# SERDES_16G0 register map
Vendor: Texas Instruments
Registers are 32-bit, read-write, reset 0x0 unless marked. A register's access mark holds for its fields unless they carry their own. Offsets are as the file gives them; [hi:lo] are bit positions; {n}, {i} and the like mark numbered series.

## SERDES_16G0 (part 5 of 5)
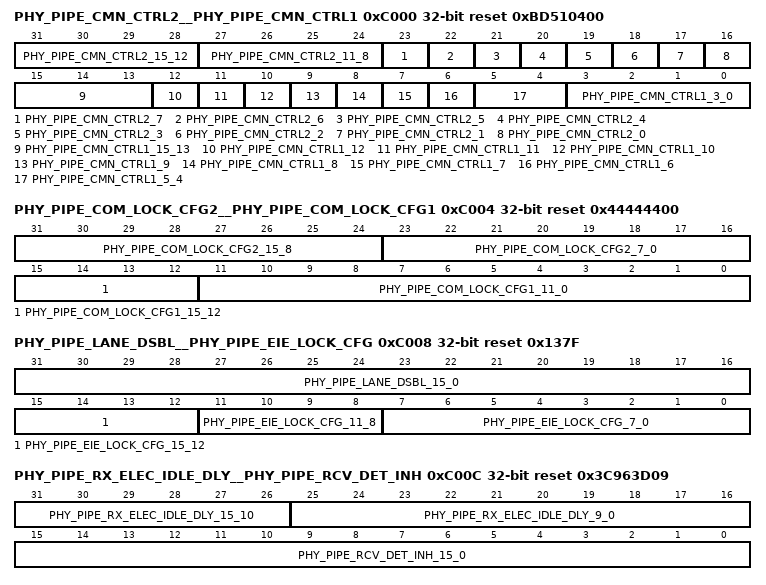
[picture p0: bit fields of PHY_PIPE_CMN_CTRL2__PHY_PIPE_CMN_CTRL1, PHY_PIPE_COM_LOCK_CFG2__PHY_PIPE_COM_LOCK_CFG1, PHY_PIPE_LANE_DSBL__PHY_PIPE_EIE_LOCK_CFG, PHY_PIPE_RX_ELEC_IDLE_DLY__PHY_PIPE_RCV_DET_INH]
0xC000 PHY_PIPE_CMN_CTRL2__PHY_PIPE_CMN_CTRL1 access not given reset 0xBD510400 — PIPE common control1 register
  [31:28] PHY_PIPE_CMN_CTRL2_15_12 rw — USB SuperSpeed Tx LFPS Stretch: Minimum number of data rate clock cycles in which PMA tx_lfps_en signal is asserted for USB SuperSpeed rate.
  [27:24] PHY_PIPE_CMN_CTRL2_11_8 rw — USB SuperSpeedPlus Tx LFPS Stretch: Minimum number of data rate clock cycles in which PMA tx_lfps_en signal is asserted for USB SuperSpeedPlus rate.
  [23] PHY_PIPE_CMN_CTRL2_7 rw — PCIe PIPE Gen 4 Rx mode:
  [22] PHY_PIPE_CMN_CTRL2_6 rw — TX electrical idle pre release: When this bit is set, the TX electrical idle release to the PMA is advanced 1 cycle to allow the adjustment of the data path timing
  [21] PHY_PIPE_CMN_CTRL2_5 rw — RX equalizer complete mask: When this bit is cleared, the PHY will return direction change of 0 when PMA indicates evaluation complete.
  [20] PHY_PIPE_CMN_CTRL2_4 rw — PCIe Gen 1/2 EIOS cycle error mask: When this bit is enabled and the pipe rx interface is outputting a PCIe Gen 1/2 EIOS symbol, decode errors will be masked out.
  [19] PHY_PIPE_CMN_CTRL2_3 rw — USB Gen 2 Bit Error Correction Disable: When this bit is high, bit error correction on SKP and SDS symbols is disabled.
  [18] PHY_PIPE_CMN_CTRL2_2 rw — USB PIPE3 Compatibility Mode enable: When this bit is set to 1, USB PIPE3 compatibility mode is enabled.
  [17] PHY_PIPE_CMN_CTRL2_1 rw — USB Loopback Slave Error Count disable: When this bit is set to 1, disables the error count for US loopback slave, such that the error count is not inserted into the BCNT OS.
  [16] PHY_PIPE_CMN_CTRL2_0 rw — USB Elasticity Buffer Re-align enable: When this bit is set to 1, when Rx for a USB link is initially started, the elasticity buffer is re-aligned to its idle point upon seeing 3 consecutive COMMAs (i.e. from TS1/TS2s) in the same relative bit position.
  [15:13] PHY_PIPE_CMN_CTRL1_15_13 ro — Reserved
  [12] PHY_PIPE_CMN_CTRL1_12 — PHY APB access timeout: When set, an APB read/write request to PHY registers failed (i.e. timed out). (access RC)
  [11] PHY_PIPE_CMN_CTRL1_11 ro — Reserved
  [10] PHY_PIPE_CMN_CTRL1_10 rw — Comma realign: This field controls the comma alignment state machine to re-align to new bit position without going to loss of sync state for Gen1/2.
  [9] PHY_PIPE_CMN_CTRL1_9 rw — Block alignment clear on EIOS Gen4: When this bit is enabled and the Gen 3/4 block alignment sees an EIOS, then the block alignment will automatically reset regardless of signal detect from the PMA.
  [8] PHY_PIPE_CMN_CTRL1_8 rw — Comma alignment clear on EIOS Gen2: When this bit is enabled and the Gen 1/2 comma alignment sees an EIOS, then the COMMA alignment will automatically reset regardless of signal detect from the PMA.
  [7] PHY_PIPE_CMN_CTRL1_7 rw — Block alignment ignore rx_sigdetect Gen4: When this signal is enabled, the PCS receive path block alignment will not clear due to loss of signal detection from the PMA in Gen 3/4 mode.
  [6] PHY_PIPE_CMN_CTRL1_6 rw — Comma alignment ignore rx_sigdetect Gen2: When this signal is enabled, the PCS receive path COMMA alignment will not clear due to loss of signal detection from the PMA in Gen 1/2 mode.
  [5:4] PHY_PIPE_CMN_CTRL1_5_4 rw — RX signal detect delay: Controls how much delay to add to the PMA signal detect to delay when the bit alignment blocks should be reset after losing signal.
  [3:0] PHY_PIPE_CMN_CTRL1_3_0 ro — Reserved
0xC004 PHY_PIPE_COM_LOCK_CFG2__PHY_PIPE_COM_LOCK_CFG1 reset 0x44444400 — PIPE comma lock configuration1 register ()
  [31:24] PHY_PIPE_COM_LOCK_CFG2_15_8 — comma lock count fast: The number of COMMA symbols that needs to be seen in the same bit position for the comma state machine to lock for Gen1/2.
  [23:16] PHY_PIPE_COM_LOCK_CFG2_7_0 — comma lock count: The number of COMMA symbols that needs to be seen in the same bit position for the comma state machine to lock for Gen1/2.
  [15:12] PHY_PIPE_COM_LOCK_CFG1_15_12 — Symbol unlock count: The number of COMMA symbols that needs to be seen in the wrong bit position before the comma alignment state machine will transition to RESYNC or LOS state for Gen1/2.
  [11:0] PHY_PIPE_COM_LOCK_CFG1_11_0 — comma full lock count: The number of COMMA symbols that needs to be seen in the same bit position for the comma alignment state machine to lock for Gen1/2.
0xC008 PHY_PIPE_LANE_DSBL__PHY_PIPE_EIE_LOCK_CFG reset 0x137F — PIPE EIEOS lock configuration register ()
  [31:16] PHY_PIPE_LANE_DSBL_15_0 — lane disable: When set the appropriate lane is disabled.
  [15:12] PHY_PIPE_EIE_LOCK_CFG_15_12 — EIE lock count fast: The number of EIEOS blocks that need to be seen in the same bit position for the alignment state machine to lock for Gen3/4.
  [11:8] PHY_PIPE_EIE_LOCK_CFG_11_8 — EIE lock count: The number of EIEOS blocks that need to be seen in the same bit position for the alignment state machine to lock for Gen3/4.
  [7:0] PHY_PIPE_EIE_LOCK_CFG_7_0 — EIE full lock count: The number of EIEOS blocks that need to be seen in the same bit position for the alignment state machine to lock for Gen3/4.
0xC00C PHY_PIPE_RX_ELEC_IDLE_DLY__PHY_PIPE_RCV_DET_INH reset 0x3C963D09 — PIPE receiver detect inhibit register ()
  [31:26] PHY_PIPE_RX_ELEC_IDLE_DLY_15_10 — L1.x exit Rx electrical idle force fast count: Counter load value to hold PIPE Rx Electrical Idle high upon exit from L1.x.
  [25:16] PHY_PIPE_RX_ELEC_IDLE_DLY_9_0 — L1.x exit Rx electrical idle force full count: Counter load value to hold PIPE Rx Electrical Idle high upon exit from L1.x when the PMA common was powered down.
  [15:0] PHY_PIPE_RCV_DET_INH_15_0 — Receiver Detect Inhibit Counter Load Value: Counter load value to delay receiver detection request to PMA until PMA common mode is within the required range.
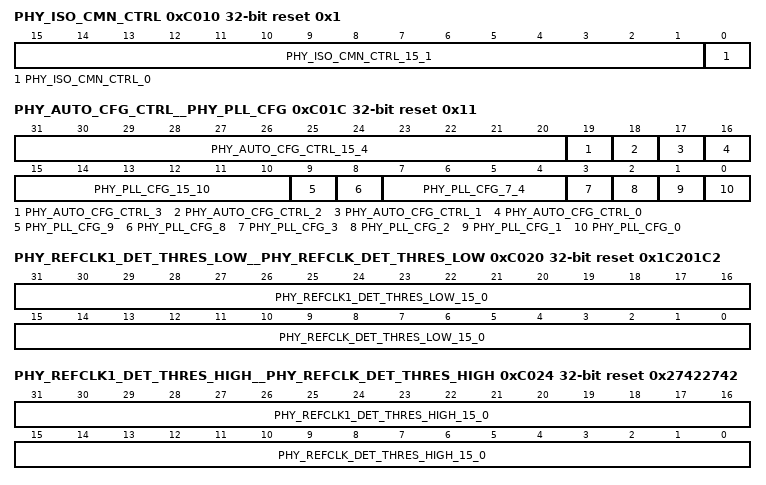
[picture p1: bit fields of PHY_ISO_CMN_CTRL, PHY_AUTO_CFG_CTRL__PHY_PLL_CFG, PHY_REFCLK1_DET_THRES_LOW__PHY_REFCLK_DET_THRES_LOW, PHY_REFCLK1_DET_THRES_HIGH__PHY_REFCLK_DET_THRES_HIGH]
0xC010 PHY_ISO_CMN_CTRL access per field reset 0x1 — PHY common control signal isolation register
  [15:1] PHY_ISO_CMN_CTRL_15_1 ro — Reserved
  [0] PHY_ISO_CMN_CTRL_0 rw — Drives the phy_reset_n PHY input when in PHY macro and PMA isolation modes.
0xC014 PHY_STATE_CHG_TIMEOUT reset 0x30D4 — PHY state change monitor timeout
  [15:0] PHY_STATE_CHG_TIMEOUT_15_0 — State change timeout: Bits [19:4] of the state change timeout (bits [3:0] are zero).
0xC01C PHY_AUTO_CFG_CTRL__PHY_PLL_CFG access per field reset 0x11 — PHY PLL configuration register
  [31:20] PHY_AUTO_CFG_CTRL_15_4 ro — Reserved
  [19] PHY_AUTO_CFG_CTRL_3 ro — Auto-configuration complete:
  [18] PHY_AUTO_CFG_CTRL_2 rw — Auto-configuration stall:
  [17] PHY_AUTO_CFG_CTRL_1 ro — Reserved
  [16] PHY_AUTO_CFG_CTRL_0 rw — Auto-configuration disable:
  [15:10] PHY_PLL_CFG_15_10 ro — Reserved
  [9] PHY_PLL_CFG_9 rw — RefClk1 disable override: When set to 1, overrides asserting cmn_refclk1_disable to the PMA high when the PMA is suspended (i.e. all links in low power state).
  [8] PHY_PLL_CFG_8 rw — RefClk disable override: When set to 1, overrides asserting cmn_refclk_disable to the PMA high when the PMA is suspended (i.e. all links in low power state).
  [7:4] PHY_PLL_CFG_7_4 rw — Dual port mode port 1 lane number: When configured for dual port mode, this field selects the master lane for port/link 1.
  [3] PHY_PLL_CFG_3 ro — Reserved
  [2] PHY_PLL_CFG_2 rw — Dual port mode enable:
  [1] PHY_PLL_CFG_1 rw — PLL LC only:
  [0] PHY_PLL_CFG_0 rw — Single link PCIe configuration:
0xC020 PHY_REFCLK1_DET_THRES_LOW__PHY_REFCLK_DET_THRES_LOW reset 0x1C201C2 — PHY external reference clock detect low threshold register
  [31:16] PHY_REFCLK1_DET_THRES_LOW_15_0 — External Reference Clock1 Active Detect Low Threshold: This is the minimum number of external reference clock cycles (on cmn_refclk1_p/m) which must be counted during the measurement interval to indicate a valid clock detected.
  [15:0] PHY_REFCLK_DET_THRES_LOW_15_0 — External Reference Clock Active Detect Low Threshold: This is the minimum number of external reference clock cycles (on cmn_refclk_p/m) which must be counted during the measurement interval to indicate a valid clock detected.
0xC024 PHY_REFCLK1_DET_THRES_HIGH__PHY_REFCLK_DET_THRES_HIGH reset 0x27422742 — PHY external reference clock detect high threshold register
  [31:16] PHY_REFCLK1_DET_THRES_HIGH_15_0 — External Reference Clock1 Active Detect High Threshold: This is the maximum number of external reference clock cycles (on cmn_refclk1_p/m) which must be counted during the measurement interval to indicate a valid clock detected.
  [15:0] PHY_REFCLK_DET_THRES_HIGH_15_0 — External Reference Clock Active Detect High Threshold: This is the maximum number of external reference clock cycles (on cmn_refclk_p/m) which must be counted during the measurement interval to indicate a valid clock detected.
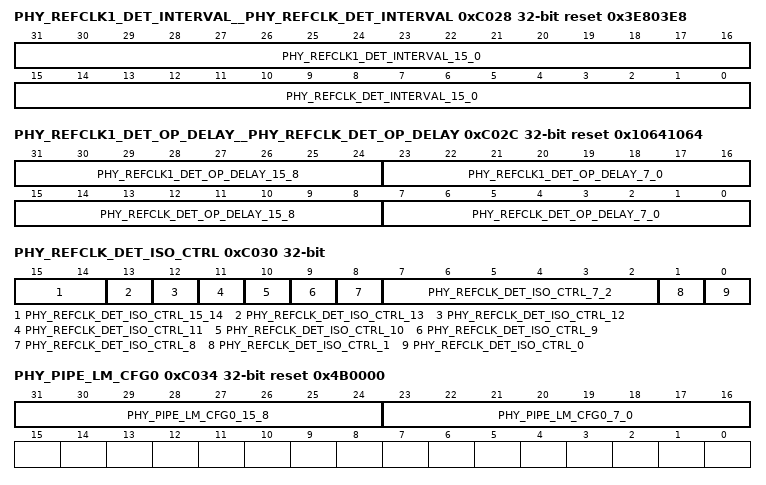
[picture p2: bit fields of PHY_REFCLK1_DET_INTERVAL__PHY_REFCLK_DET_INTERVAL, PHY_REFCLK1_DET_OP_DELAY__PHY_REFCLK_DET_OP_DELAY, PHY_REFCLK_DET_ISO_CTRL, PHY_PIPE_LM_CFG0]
0xC028 PHY_REFCLK1_DET_INTERVAL__PHY_REFCLK_DET_INTERVAL reset 0x3E803E8 — PHY external reference clock detect measurement interval register
  [31:16] PHY_REFCLK1_DET_INTERVAL_15_0 — External Reference Clock1 Active Detect Measurement Interval: This is the number of apb_pclk cycles in which to count external reference clock cycles (on cmn_refclk1_p/m).
  [15:0] PHY_REFCLK_DET_INTERVAL_15_0 — External Reference Clock Active Detect Measurement Interval: This is the number of apb_pclk cycles in which to count external reference clock cycles (on cmn_refclk_p/m).
0xC02C PHY_REFCLK1_DET_OP_DELAY__PHY_REFCLK_DET_OP_DELAY reset 0x10641064 — PHY external reference clock detect delay register
  [31:24] PHY_REFCLK1_DET_OP_DELAY_15_8 — External Reference Clock1 Active Detect End Delay: This is the number of apb_pclk cycles to wait upon completion of measurement interval before capturing the result (accounts for synchronization delays) for measurement on cmn_refclk1_p/m.
  [23:16] PHY_REFCLK1_DET_OP_DELAY_7_0 — External Reference Clock1 Active Detect Start Delay: This is the number of apb_pclk cycles to wait prior to start of measurement interval (accounts for enable delay of reference clock in PMA) for measurement on cmn_refclk1_p/m.
  [15:8] PHY_REFCLK_DET_OP_DELAY_15_8 — External Reference Clock Active Detect End Delay: This is the number of apb_pclk cycles to wait upon completion of measurement interval before capturing the result (accounts for synchronization delays) for measurement on cmn_refclk_p/m.
  [7:0] PHY_REFCLK_DET_OP_DELAY_7_0 — External Reference Clock Active Detect Start Delay: This is the number of apb_pclk cycles to wait prior to start of measurement interval (accounts for enable delay of reference clock in PMA) for measurement on cmn_refclk_p/m.
0xC030 PHY_REFCLK_DET_ISO_CTRL access per field — PHY external reference clock detect isolation control register
  [15:14] PHY_REFCLK_DET_ISO_CTRL_15_14 ro — Reserved
  [13] PHY_REFCLK_DET_ISO_CTRL_13 ro — Captures the current value of the pma_cmn_ext_refclk1_detected_cfg PHY input.
  [12] PHY_REFCLK_DET_ISO_CTRL_12 ro — Captures the current value of the pma_cmn_ext_refclk_detected_cfg PHY input.
  [11] PHY_REFCLK_DET_ISO_CTRL_11 ro — Current value of pma_cmn_ext_refclk1_detected PHY output.
  [10] PHY_REFCLK_DET_ISO_CTRL_10 ro — Current value of pma_cmn_ext_refclk1_detected_valid PHY output.
  [9] PHY_REFCLK_DET_ISO_CTRL_9 ro — Current value of pma_cmn_ext_refclk_detected PHY output.
  [8] PHY_REFCLK_DET_ISO_CTRL_8 ro — Current value of pma_cmn_ext_refclk_detected_valid PHY output.
  [7:2] PHY_REFCLK_DET_ISO_CTRL_7_2 ro — Reserved
  [1] PHY_REFCLK_DET_ISO_CTRL_1 wo — External Reference Clock1 Active Detect Start: Write with 1 to initiate an external reference clock active detect operation on cmn_refclk1_p/m.
  [0] PHY_REFCLK_DET_ISO_CTRL_0 wo — External Reference Clock Active Detect Start: Write with 1 to initiate an external reference clock active detect operation on cmn_refclk_p/m.
0xC034 PHY_PIPE_LM_CFG0 access per field reset 0x4B0000 — PHY PIPE lane margining configuration 0 register (#)
  [31:24] PHY_PIPE_LM_CFG0_15_8 ro — Reserved
  [23:16] PHY_PIPE_LM_CFG0_7_0 rw — Lane margining direction configuration: Maps the PIPE margin direction encoding to the PMA margin direction encoding:
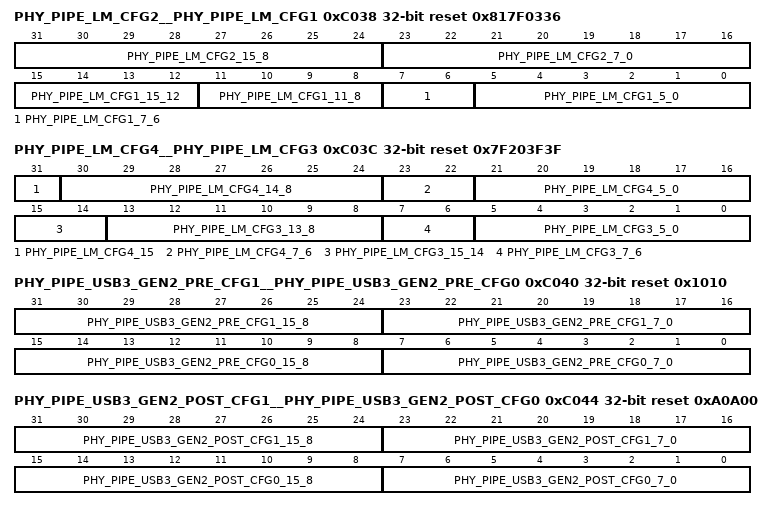
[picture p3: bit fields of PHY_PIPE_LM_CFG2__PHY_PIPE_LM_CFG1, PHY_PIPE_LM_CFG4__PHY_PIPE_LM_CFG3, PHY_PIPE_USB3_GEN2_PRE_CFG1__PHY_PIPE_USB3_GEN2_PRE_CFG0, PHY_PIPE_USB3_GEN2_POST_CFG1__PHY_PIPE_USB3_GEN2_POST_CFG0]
0xC038 PHY_PIPE_LM_CFG2__PHY_PIPE_LM_CFG1 access per field reset 0x817F0336 — PHY PIPE lane margining configuration 1 register (#)
  [31:24] PHY_PIPE_LM_CFG2_15_8 rw — Lane margining sample count threshold: This is the sample count saturation point.
  [23:16] PHY_PIPE_LM_CFG2_7_0 rw — Lane margining sample count maximum: This is sample count value reported whenever total sample count value X= sample count threshold (bits [15:8]).
  [15:12] PHY_PIPE_LM_CFG1_15_12 ro — Reserved
  [11:8] PHY_PIPE_LM_CFG1_11_8 rw — Lane margining wait time: This is wait time at PMA interface between setting PMA inputs rx_mrgn_offset and rx_mrgn_dir before asserting rx_mrgn_req.
  [7:6] PHY_PIPE_LM_CFG1_7_6 ro — Reserved
  [5:0] PHY_PIPE_LM_CFG1_5_0 rw — Lane margining sample count 3 logn value: This is the value of 3 * logn (number of samples per PMA eye surf iteration).
0xC03C PHY_PIPE_LM_CFG4__PHY_PIPE_LM_CFG3 access per field reset 0x7F203F3F — PHY PIPE lane margining configuration 3 register (#)
  [31] PHY_PIPE_LM_CFG4_15 ro — Reserved
  [30:24] PHY_PIPE_LM_CFG4_14_8 rw — Lane margining maximum voltage offset: This is the maximum voltage offset supported by the PMA.
  [23:22] PHY_PIPE_LM_CFG4_7_6 ro — Reserved
  [21:16] PHY_PIPE_LM_CFG4_5_0 rw — Lane margining maximum timing offset: This is the maximum timing offset supported by the PMA
  [15:14] PHY_PIPE_LM_CFG3_15_14 ro — Reserved
  [13:8] PHY_PIPE_LM_CFG3_13_8 rw — Lane margining error count threshold: Maximum total error count.
  [7:6] PHY_PIPE_LM_CFG3_7_6 ro — Reserved
  [5:0] PHY_PIPE_LM_CFG3_5_0 rw — Lane margining error count maximum: This is the error count reported, whenever the total error count value X= error count threshold (bits [13:8]).
0xC040 PHY_PIPE_USB3_GEN2_PRE_CFG1__PHY_PIPE_USB3_GEN2_PRE_CFG0 reset 0x1010 — PHY USB3 Gen 2 pre-shoot configuration 0 register ()
  [31:24] PHY_PIPE_USB3_GEN2_PRE_CFG1_15_8 — USB3 Gen 2 transmit pre-shoot multiplier configuration
  [23:16] PHY_PIPE_USB3_GEN2_PRE_CFG1_7_0 — USB3 Gen 2 transmit pre-shoot multiplier configuration
  [15:8] PHY_PIPE_USB3_GEN2_PRE_CFG0_15_8 — USB3 Gen 2 transmit pre-shoot multiplier configuration
  [7:0] PHY_PIPE_USB3_GEN2_PRE_CFG0_7_0 — USB3 Gen 2 transmit pre-shoot multiplier configuration
0xC044 PHY_PIPE_USB3_GEN2_POST_CFG1__PHY_PIPE_USB3_GEN2_POST_CFG0 reset 0xA0A00 — PHY USB3 Gen 2 de-emphasis configuration 0 register ()
  [31:24] PHY_PIPE_USB3_GEN2_POST_CFG1_15_8 — USB3 Gen 2 transmit pre-shoot multiplier configuration 3: For a
  [23:16] PHY_PIPE_USB3_GEN2_POST_CFG1_7_0 — USB3 Gen 2 transmit pre-shoot multiplier configuration 2: For a lane configured for USB3 mode at Gen 3 data rate, sets the multiplier configuration for the Tx de-emphasis (C1) when pipe_lXX_tx_deemphasis[1:0] == 0b10 for the associated lane.
  [15:8] PHY_PIPE_USB3_GEN2_POST_CFG0_15_8 — USB3 Gen 2 transmit pre-shoot multiplier configuration 1: For a lane configured for USB3 mode at Gen 3 data rate, sets the multiplier configuration for the Tx de-emphasis (C1) when pipe_lXX_tx_deemphasis[1:0] == 0b01 for the associated lane.
  [7:0] PHY_PIPE_USB3_GEN2_POST_CFG0_7_0 — USB3 Gen 2 transmit pre-shoot multiplier configuration
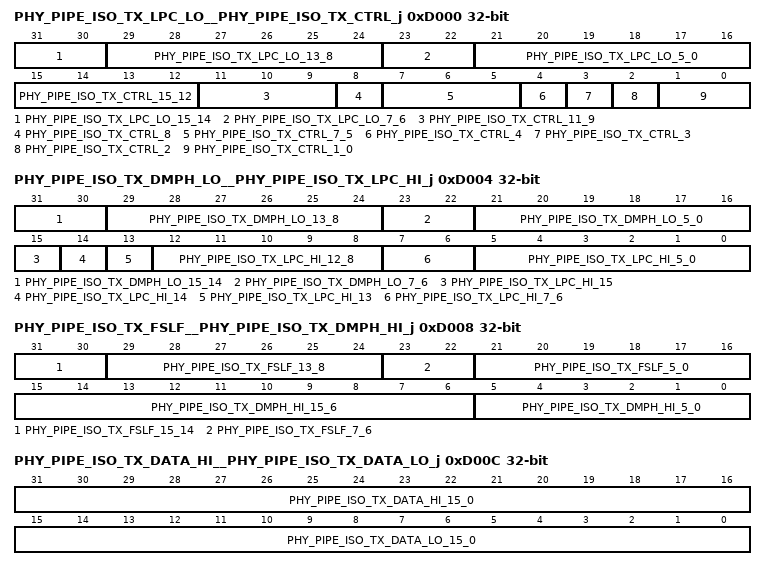
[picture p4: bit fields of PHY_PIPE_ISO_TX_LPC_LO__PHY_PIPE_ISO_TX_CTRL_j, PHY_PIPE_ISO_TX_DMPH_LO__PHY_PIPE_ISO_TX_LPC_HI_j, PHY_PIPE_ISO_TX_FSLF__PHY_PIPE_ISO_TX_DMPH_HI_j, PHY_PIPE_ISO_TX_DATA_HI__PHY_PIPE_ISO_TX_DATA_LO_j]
0xD000 PHY_PIPE_ISO_TX_LPC_LO__PHY_PIPE_ISO_TX_CTRL_j access per field — PIPE TX control signal isolation register () Offset = D000h + (j * 200h); where j = 0h to 1h
  [31:30] PHY_PIPE_ISO_TX_LPC_LO_15_14 ro — Reserved
  [29:24] PHY_PIPE_ISO_TX_LPC_LO_13_8 ro — Current value of pipe_tx_local_tx_preset_coefficients[11:6] for the associated lane when PHY_PCS_ISO_TX_LPC_HI[15] == 1.
  [23:22] PHY_PIPE_ISO_TX_LPC_LO_7_6 ro — Reserved
  [21:16] PHY_PIPE_ISO_TX_LPC_LO_5_0 ro — Current value of pipe_tx_local_tx_preset_coefficients[5:0] for the associated lane when PHY_PCS_ISO_TX_LPC_HI[15] == 1.
  [15:12] PHY_PIPE_ISO_TX_CTRL_15_12 rw — Drives pipe_tx_data_k PHY input for the associated lane when in PHY macro and PMA isolation modes.
  [11:9] PHY_PIPE_ISO_TX_CTRL_11_9 ro — Reserved
  [8] PHY_PIPE_ISO_TX_CTRL_8 rw — Drives pipe_tx_ones_zeros input for the associated lane when in PHY macro and PMA isolation modes.
  [7:5] PHY_PIPE_ISO_TX_CTRL_7_5 ro — Reserved
  [4] PHY_PIPE_ISO_TX_CTRL_4 rw — Drives pipe_tx_elec_idle PHY input for the associated lane when in PHY macro and PMA isolation modes.
  [3] PHY_PIPE_ISO_TX_CTRL_3 rw — Drives pipe_tx_128b_enc_byp PHY input for the associated lane when in PHY macro and PMA isolation modes.
  [2] PHY_PIPE_ISO_TX_CTRL_2 rw — Drives pipe_tx_compliance PHY input for the associated lane when in PHY macro and PMA isolation modes.
  [1:0] PHY_PIPE_ISO_TX_CTRL_1_0 rw — Drives pipe_tx_pattern PHY input for the associated lane when in PHY macro and PMA isolation modes.
0xD004 PHY_PIPE_ISO_TX_DMPH_LO__PHY_PIPE_ISO_TX_LPC_HI_j access per field — PIPE TX local preset coefficients high isolation register () Offset = D004h + (j * 200h); where j = 0h to 1h
  [31:30] PHY_PIPE_ISO_TX_DMPH_LO_15_14 ro — Reserved
  [29:24] PHY_PIPE_ISO_TX_DMPH_LO_13_8 rw — Drives pipe_tx_deemph[11:6] PHY input for the associated lane when in PHY macro and PMA isolation modes.
  [23:22] PHY_PIPE_ISO_TX_DMPH_LO_7_6 ro — Reserved
  [21:16] PHY_PIPE_ISO_TX_DMPH_LO_5_0 rw — Drives pipe_tx_deemph[5:0] PHY input for the associated lane when in PHY macro and PMA isolation modes.
  [15] PHY_PIPE_ISO_TX_LPC_HI_15 ro — Set upon assertion of pipe_tx_local_tx_coeff_vld PHY output for the associated lane.
  [14] PHY_PIPE_ISO_TX_LPC_HI_14 ro — Reserved
  [13] PHY_PIPE_ISO_TX_LPC_HI_13 rw — Drives pipe_tx_get_local_preset_coef PHY output for the associated lane when in PHY macro and PMA isolation modes
  [12:8] PHY_PIPE_ISO_TX_LPC_HI_12_8 rw — Drives pipe_tx_local_preset_index PHY output for the associated lane when in PHY macro and PMA isolation modes.
  [7:6] PHY_PIPE_ISO_TX_LPC_HI_7_6 ro — Reserved
  [5:0] PHY_PIPE_ISO_TX_LPC_HI_5_0 ro — Current value of pipe_tx_local_tx_preset_coefficients[17:12] for the associated lane when PHY_PCS_ISO_TX_LPC_HI[15] == 1.
0xD008 PHY_PIPE_ISO_TX_FSLF__PHY_PIPE_ISO_TX_DMPH_HI_j access per field — PIPE TX deemphasis isolation register () Offset = D008h + (j * 200h); where j = 0h to 1h
  [31:30] PHY_PIPE_ISO_TX_FSLF_15_14 ro — Reserved
  [29:24] PHY_PIPE_ISO_TX_FSLF_13_8 ro — Current value of pipe_tx_local_fs PHY output for the associated lane.
  [23:22] PHY_PIPE_ISO_TX_FSLF_7_6 ro — Reserved
  [21:16] PHY_PIPE_ISO_TX_FSLF_5_0 ro — Current value of pipe_tx_local_lf PHY output for the associated lane.
  [15:6] PHY_PIPE_ISO_TX_DMPH_HI_15_6 ro — Reserved
  [5:0] PHY_PIPE_ISO_TX_DMPH_HI_5_0 rw — Drives pipe_tx_deemph[17:12] PHY input for the associated lane when in PHY macro and PMA isolation modes.
0xD00C PHY_PIPE_ISO_TX_DATA_HI__PHY_PIPE_ISO_TX_DATA_LO_j — PIPE TX data lower isolation register () Offset = D00Ch + (j * 200h); where j = 0h to 1h
  [31:16] PHY_PIPE_ISO_TX_DATA_HI_15_0 — Drives pipe_tx_data[31:16] PHY input for the associated lane when in PHY macro and PMA isolation modes.
  [15:0] PHY_PIPE_ISO_TX_DATA_LO_15_0 — Drives pipe_tx_data[15:0] PHY input for the associated lane when in PHY macro and PMA isolation modes.
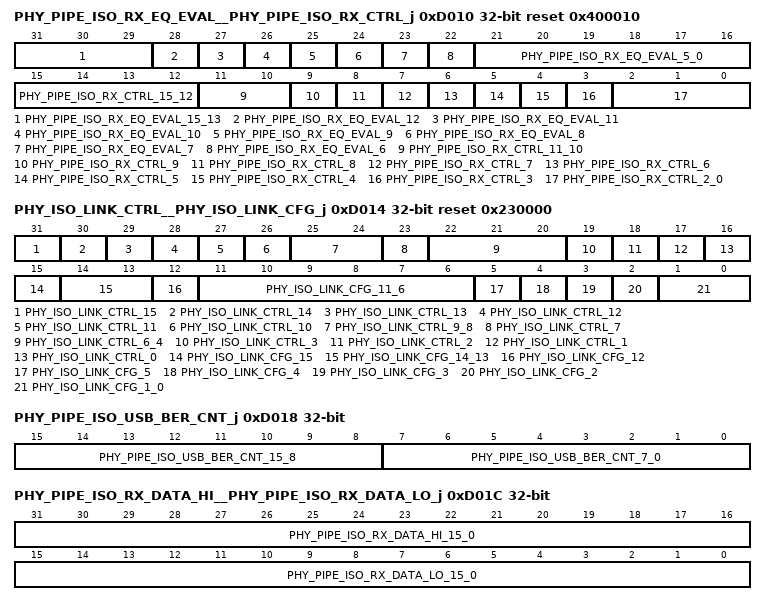
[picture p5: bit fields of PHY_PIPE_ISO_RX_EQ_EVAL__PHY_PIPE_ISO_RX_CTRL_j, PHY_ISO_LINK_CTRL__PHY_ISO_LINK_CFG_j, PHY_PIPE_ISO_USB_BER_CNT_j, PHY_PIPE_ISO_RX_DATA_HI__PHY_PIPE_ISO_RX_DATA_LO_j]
0xD010 PHY_PIPE_ISO_RX_EQ_EVAL__PHY_PIPE_ISO_RX_CTRL_j access per field reset 0x400010 — PIPE RX control signal isolation register () Offset = D010h + (j * 200h); where j = 0h to 1h
  [31:29] PHY_PIPE_ISO_RX_EQ_EVAL_15_13 ro — Reserved
  [28] PHY_PIPE_ISO_RX_EQ_EVAL_12 rw — Drives pipe_rx_invalid_request PHY input for the associated lane when in PHY macro and PMA isolation modes.
  [27] PHY_PIPE_ISO_RX_EQ_EVAL_11 rw — pipe_link_eval_dir_change[5:4] bit reversal enable.
  [26] PHY_PIPE_ISO_RX_EQ_EVAL_10 rw — pipe_link_eval_dir_change[3:2] bit reversal enable.
  [25] PHY_PIPE_ISO_RX_EQ_EVAL_9 rw — pipe_link_eval_dir_change[1:0] bit reversal enable.
  [24] PHY_PIPE_ISO_RX_EQ_EVAL_8 rw — Drives pipe_rx_eval PHY input for the associated lane when in PHY macro and PMA isolation modes.
  [23] PHY_PIPE_ISO_RX_EQ_EVAL_7 ro — Reserved
  [22] PHY_PIPE_ISO_RX_EQ_EVAL_6 ro — Captures pipe_phy_status for Rx equalization evaluation PHY output for the associated lane (does not include power state change signaling).
  [21:16] PHY_PIPE_ISO_RX_EQ_EVAL_5_0 ro — pipe_link_eval_dir_change PHY output for the associated lane (prior to bit reversal logic) upon completion of Rx equalization evaluation.
  [15:12] PHY_PIPE_ISO_RX_CTRL_15_12 ro — Current value of pipe_rx_data_k PHY output for the associated lane, when PHY_PCS_ISO_RX_CTRL[6] == 1. Otherwise, 0.
  [11:10] PHY_PIPE_ISO_RX_CTRL_11_10 ro — Reserved
  [9] PHY_PIPE_ISO_RX_CTRL_9 rw — Drives pipe_rx_eq_training PHY input for the associated lane when in PHY macro and PMA isolation modes.
  [8] PHY_PIPE_ISO_RX_CTRL_8 rw — Drives pipe_rx_termination PHY input for the associated lane when in PHY macro and PMA isolation modes.
  [7] PHY_PIPE_ISO_RX_CTRL_7 rw — Drives pipe_rx_polarity PHY output for the associated lane when in PHY macro and PMA isolation modes.
  [6] PHY_PIPE_ISO_RX_CTRL_6 ro — Reserved
  [5] PHY_PIPE_ISO_RX_CTRL_5 ro — Current value of pipe_rx_valid PHY output for the associated lane.
  [4] PHY_PIPE_ISO_RX_CTRL_4 ro — Current value of pipe_rx_elec_idle PHY output for the associated lane.
  [3] PHY_PIPE_ISO_RX_CTRL_3 ro — Captures pipe_align_detect for PHY output for the associated lane.
  [2:0] PHY_PIPE_ISO_RX_CTRL_2_0 ro — Current value of pipe_rx_status PHY output for the associated lane.
0xD014 PHY_ISO_LINK_CTRL__PHY_ISO_LINK_CFG_j access per field reset 0x230000 — PHY Link configuration isolation register Offset = D014h + (j * 200h); where j = 0h to 1h
  [31] PHY_ISO_LINK_CTRL_15 ro — Current value of pma_l{nnnn}_pwr_en_ack PHY output.
  [30] PHY_ISO_LINK_CTRL_14 rw — Drives pma_l{nnnn}_pwr_en PHY input when in PHY macro and PMA isolation modes.
  [29] PHY_ISO_LINK_CTRL_13 ro — Current value of phy_l{nnnn}_ack_l1_x PHY output.
  [28] PHY_ISO_LINK_CTRL_12 rw — Drives phy_l{nnnn}_ent_l1_x PHY input when in PHY macro and PMA isolation modes.
  [27] PHY_ISO_LINK_CTRL_11 rw — Drives phy_l{nnnn}_rx_elec_idle_det_en PHY input when in PHY macro and PMA isolation modes.
  [26] PHY_ISO_LINK_CTRL_10 rw — Drives phy_l{nnnn}_tx_cmn_mode_en PHY input when in PHY macro and PMA isolation modes.
  [25:24] PHY_ISO_LINK_CTRL_9_8 rw — Drives pipe_l{nnnn}_rate PHY input when in PHY macro and PMA isolation modes.
  [23] PHY_ISO_LINK_CTRL_7 ro — Reserved
  [22:20] PHY_ISO_LINK_CTRL_6_4 rw — Drives pipe_l{nnnn}_powerdown PHY input when in PHY macro and PMA isolation modes.
  [19] PHY_ISO_LINK_CTRL_3 ro — Reserved
  [18] PHY_ISO_LINK_CTRL_2 rw — Drives pipe_l{nnnn}_tx_det_rx_lpbk PHY input when in PHY macro and PMA isolation modes.
  [17] PHY_ISO_LINK_CTRL_1 ro — Captures pipe_l{nnnn}_ phy_status for power state change PHY output (does not include Rx equalization signaling).
  [16] PHY_ISO_LINK_CTRL_0 rw — Drives phy_l{nnnn}_reset_n PHY input when in PHY macro and PMA isolation modes.
  [15] PHY_ISO_LINK_CFG_15 rw — Drives phy_link_cfg_ln_{nnnn} PHY input when in PHY macro and PMA isolation modes.
  [14:13] PHY_ISO_LINK_CFG_14_13 ro — Reserved
  [12] PHY_ISO_LINK_CFG_12 rw — Drives pipe_l{nnnn}_32bit_sel PHY input when in PHY macro and PMA isolation modes.
  [11:6] PHY_ISO_LINK_CFG_11_6 ro — Reserved
  [5] PHY_ISO_LINK_CFG_5 rw — Drives phy_l{nnnn}_pcie_l1_ss_sel PHY input when in PHY macro and PMA isolation modes.
  [4] PHY_ISO_LINK_CFG_4 rw — Drives pipe_l{nnnn}_eb_mode PHY input when in PHY macro and PMA isolation modes.
  [3] PHY_ISO_LINK_CFG_3 rw — Drives phy_eth_mode PHY input for the associated lane when in PHY macro and PMA isolation modes.
  [2] PHY_ISO_LINK_CFG_2 rw — Drives phy_eth_mode_en PHY input for the associated lane when in PHY macro and PMA isolation modes.
  [1:0] PHY_ISO_LINK_CFG_1_0 rw — Drives phy_l{nnnn}_mode PHY input when in PHY macro and PMA isolation modes.
0xD018 PHY_PIPE_ISO_USB_BER_CNT_j ro — PIPE USB loopback slave BER count register () Offset = D018h + (j * 200h); where j = 0h to 1h
  [15:8] PHY_PIPE_ISO_USB_BER_CNT_15_8 — Reserved
  [7:0] PHY_PIPE_ISO_USB_BER_CNT_7_0 — Current value of USB 3.0 loopback slave Bit Error Count from the PCS.
0xD01C PHY_PIPE_ISO_RX_DATA_HI__PHY_PIPE_ISO_RX_DATA_LO_j ro — PIPE RX data low isolation register () Offset = D01Ch + (j * 200h); where j = 0h to 1h
  [31:16] PHY_PIPE_ISO_RX_DATA_HI_15_0 — Current value of pipe_rx_data[31:16] PHY output for the associated lane.
  [15:0] PHY_PIPE_ISO_RX_DATA_LO_15_0 — Current value of pipe_rx_data[15:0] PHY output for the associated lane.
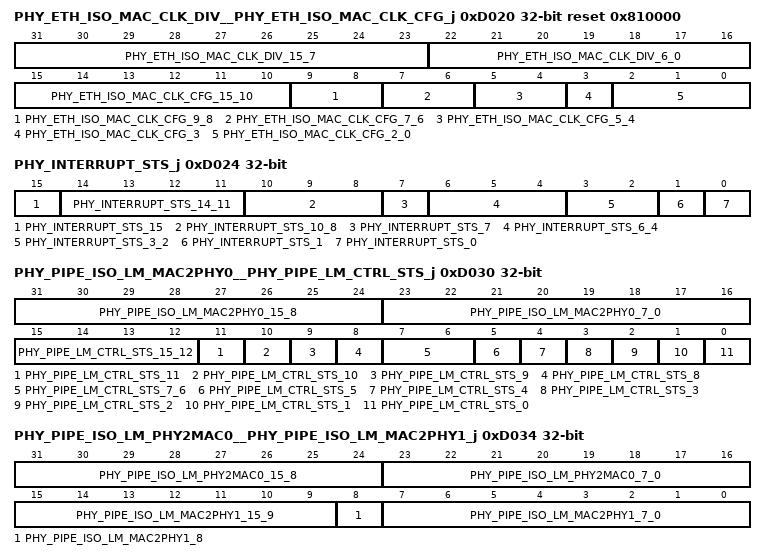
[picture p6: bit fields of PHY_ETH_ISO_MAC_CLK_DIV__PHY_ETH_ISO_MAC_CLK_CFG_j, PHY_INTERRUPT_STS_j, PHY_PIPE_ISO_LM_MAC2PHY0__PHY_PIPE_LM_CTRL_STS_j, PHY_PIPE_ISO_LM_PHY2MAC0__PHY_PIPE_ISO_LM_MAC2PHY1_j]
0xD020 PHY_ETH_ISO_MAC_CLK_DIV__PHY_ETH_ISO_MAC_CLK_CFG_j access per field reset 0x810000 — Ethernet MAC clock configuration isolation register Offset = D020h + (j * 200h); where j = 0h to 1h
  [31:23] PHY_ETH_ISO_MAC_CLK_DIV_15_7 rw — Drives mac_div_sel1 PHY input for the associated lane when in PHY macro and PMA isolation mode.
  [22:16] PHY_ETH_ISO_MAC_CLK_DIV_6_0 rw — Drives mac_div_sel0 PHY input for the associated lane when in PHY macro and PMA isolation mode.
  [15:10] PHY_ETH_ISO_MAC_CLK_CFG_15_10 ro — Reserved
  [9:8] PHY_ETH_ISO_MAC_CLK_CFG_9_8 rw — Drives mac_src_sel PHY input for the associated lane when in PHY macro and PMA isolation mode.
  [7:6] PHY_ETH_ISO_MAC_CLK_CFG_7_6 ro — Reserved
  [5:4] PHY_ETH_ISO_MAC_CLK_CFG_5_4 rw — Drives ovr_src_sel PHY input for the associated lane when in PHY macro and PMA isolation mode.
  [3] PHY_ETH_ISO_MAC_CLK_CFG_3 ro — Reserved
  [2:0] PHY_ETH_ISO_MAC_CLK_CFG_2_0 rw — Drives ovr_div_sel PHY input for the associated lane when in PHY macro and PMA isolation mode.
0xD024 PHY_INTERRUPT_STS_j access per field — PHY interrupt status register Offset = D024h + (j * 200h); where j = 0h to 1h
  [15] PHY_INTERRUPT_STS_15 rw — State change monitor enable -
  [14:11] PHY_INTERRUPT_STS_14_11 ro — Reserved
  [10:8] PHY_INTERRUPT_STS_10_8 ro — Next power state/data rate - Only valid when one of the interrupt status bits is set.
  [7] PHY_INTERRUPT_STS_7 ro — Reserved
  [6:4] PHY_INTERRUPT_STS_6_4 ro — Current power state/data rate - Only valid when one of the interrupt status bits is set.
  [3:2] PHY_INTERRUPT_STS_3_2 ro — Reserved
  [1] PHY_INTERRUPT_STS_1 rw — Data rate state change interrupt status - Set to 1 upon data rate change timeout.
  [0] PHY_INTERRUPT_STS_0 rw — Power state change interrupt status - Set to 1 upon power state change timeout.
0xD030 PHY_PIPE_ISO_LM_MAC2PHY0__PHY_PIPE_LM_CTRL_STS_j access per field — PHY PIPE lane margining control and status register (#) Offset = D030h + (j * 200h); where j = 0h to 1h
  [31:24] PHY_PIPE_ISO_LM_MAC2PHY0_15_8 rw — When in PHY isolation mode, this field provides the data for the 2nd cycle of a MAC-to-PHY register interface operation (for operations that require 2 or more cycle).
  [23:16] PHY_PIPE_ISO_LM_MAC2PHY0_7_0 rw — When in PHY isolation mode, this field provides the data for the 1st cycle of a MAC-to-PHY register interface operation.
  [15:12] PHY_PIPE_LM_CTRL_STS_15_12 ro — Reserved
  [11] PHY_PIPE_LM_CTRL_STS_11 ro — Error count saturated flag: When set to 1, the error counter for the associated lane has saturated.
  [10] PHY_PIPE_LM_CTRL_STS_10 ro — Sample count saturated flag: When set to 1, the sample counter for the associated lane has saturated.
  [9] PHY_PIPE_LM_CTRL_STS_9 ro — Committed write invalid address error: When set to 1, an invalid register address was received on the PIPE MAC-to-PHY register interface for a committed write operation for the associated lane.
  [8] PHY_PIPE_LM_CTRL_STS_8 ro — Uncommitted write invalid address error: When set to 1, an invalid register address was received on the PIPE MAC-to-PHY register interface for an uncommitted write operation for the associated lane.
  [7:6] PHY_PIPE_LM_CTRL_STS_7_6 ro — Reserved
  [5] PHY_PIPE_LM_CTRL_STS_5 rw — Lane margining enable:
  [4] PHY_PIPE_LM_CTRL_STS_4 rw — Lane margining controller soft reset: Soft reset to the associated lane's lane margining controller block (i.e.
  [3] PHY_PIPE_LM_CTRL_STS_3 rw — Lane margining PMA I/F soft reset: Soft reset to the associated lane's lane margining PMA interface block (i.e. MAC-XPHY).
  [2] PHY_PIPE_LM_CTRL_STS_2 rw — Lane margining PIPE Tx I/F soft reset: Soft reset to the associated lane's lane margining PIPE transmit block (i.e. MAC-XPHY).
  [1] PHY_PIPE_LM_CTRL_STS_1 rw — Lane margining PIPE Rx I/F soft reset: Soft reset to the associated lane's lane margining PIPE receive block (i.e. MAC-XPHY).
  [0] PHY_PIPE_LM_CTRL_STS_0 rw — Lane margining soft reset: Soft reset to the associated lane's lane margining logic.
0xD034 PHY_PIPE_ISO_LM_PHY2MAC0__PHY_PIPE_ISO_LM_MAC2PHY1_j access per field — PHY PIPE lane margining MAC-to-PHY isolation register 1 (#) Offset = D034h + (j * 200h); where j = 0h to 1h
  [31:24] PHY_PIPE_ISO_LM_PHY2MAC0_15_8 ro — Captures the data from a PHY-to-MAC write (committed or uncommitted) operation to address 1.
  [23:16] PHY_PIPE_ISO_LM_PHY2MAC0_7_0 ro — Captures the data from a PHY-to-MAC write (committed or uncommitted) operation to address 0.
  [15:9] PHY_PIPE_ISO_LM_MAC2PHY1_15_9 ro — Reserved
  [8] PHY_PIPE_ISO_LM_MAC2PHY1_8 rw — When in PHY isolation mode, write a 1 to this bit to initiate a MAC-to-PHY register interface operation.
  [7:0] PHY_PIPE_ISO_LM_MAC2PHY1_7_0 rw — When in PHY isolation mode, this field provides the data for the 3rd cycle of a MAC-to-PHY register interface operation.
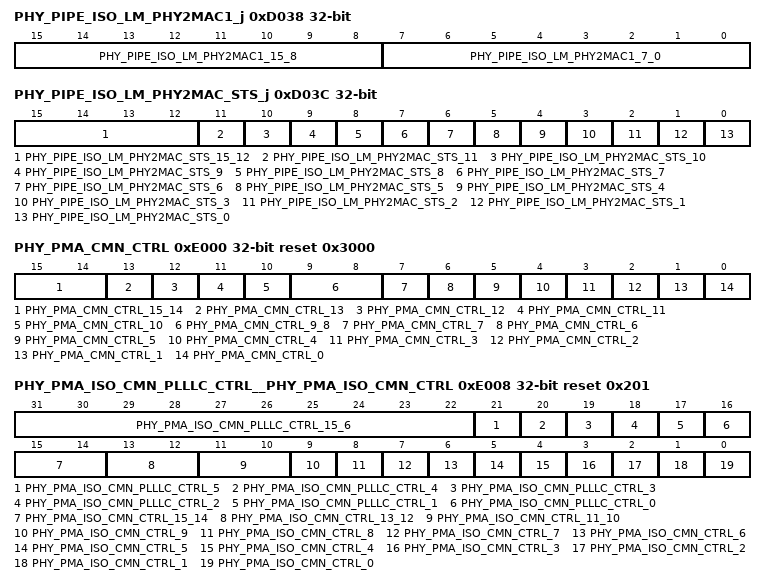
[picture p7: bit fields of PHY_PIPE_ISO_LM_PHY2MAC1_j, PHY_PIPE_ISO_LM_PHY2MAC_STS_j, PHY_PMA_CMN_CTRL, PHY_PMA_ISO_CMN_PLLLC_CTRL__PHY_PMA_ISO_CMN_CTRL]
0xD038 PHY_PIPE_ISO_LM_PHY2MAC1_j ro — PHY PIPE lane margining PHY-to-MAC isolation register 1 (#) Offset = D038h + (j * 200h); where j = 0h to 1h
  [15:8] PHY_PIPE_ISO_LM_PHY2MAC1_15_8 — Captures the data from a PHY-to-MAC read completion operation.
  [7:0] PHY_PIPE_ISO_LM_PHY2MAC1_7_0 — Captures the data from a PHY-to-MAC write (committed or uncommitted) operation to address 2.
0xD03C PHY_PIPE_ISO_LM_PHY2MAC_STS_j ro — PHY PIPE lane margining PHY-to-MAC status isolation register 1 (#) Offset = D03Ch + (j * 200h); where j = 0h to 1h
  [15:12] PHY_PIPE_ISO_LM_PHY2MAC_STS_15_12 — Reserved
  [11] PHY_PIPE_ISO_LM_PHY2MAC_STS_11 — Set upon receiving a PHY-to-MAC read completion.
  [10] PHY_PIPE_ISO_LM_PHY2MAC_STS_10 — Set upon receiving a PHY-to-MAC write acknowledgment.
  [9] PHY_PIPE_ISO_LM_PHY2MAC_STS_9 — Set upon receiving a PHY-to-MAC committed write to an unsupported address.
  [8] PHY_PIPE_ISO_LM_PHY2MAC_STS_8 — Reserved
  [7] PHY_PIPE_ISO_LM_PHY2MAC_STS_7 — Set upon receiving a PHY-to-MAC committed write to address 2.
  [6] PHY_PIPE_ISO_LM_PHY2MAC_STS_6 — Set upon receiving a PHY-to-MAC committed write to address 1.
  [5] PHY_PIPE_ISO_LM_PHY2MAC_STS_5 — Set upon receiving a PHY-to-MAC committed write to address 0.
  [4] PHY_PIPE_ISO_LM_PHY2MAC_STS_4 — Set upon receiving a PHY-to-MAC uncommitted write to an unsupported address.
  [3] PHY_PIPE_ISO_LM_PHY2MAC_STS_3 — Reserved
  [2] PHY_PIPE_ISO_LM_PHY2MAC_STS_2 — Set upon receiving a PHY-to-MAC uncommitted write to address 2.
  [1] PHY_PIPE_ISO_LM_PHY2MAC_STS_1 — Set upon receiving a PHY-to-MAC uncommitted write to address 1.
  [0] PHY_PIPE_ISO_LM_PHY2MAC_STS_0 — Set upon receiving a PHY-to-MAC uncommitted write to address 0.
0xE000 PHY_PMA_CMN_CTRL access per field reset 0x3000 — PMA common control register
  [15:14] PHY_PMA_CMN_CTRL_15_14 rw — Drives cmn_psmclk_dig_div PMA input
  [13] PHY_PMA_CMN_CTRL_13 ro — Current value of cmn_plllc1_disabled PMA output
  [12] PHY_PMA_CMN_CTRL_12 ro — Current value of cmn_plllc_disabled PMA output
  [11] PHY_PMA_CMN_CTRL_11 ro — Current value of cmn_plllc1_ready PMA output
  [10] PHY_PMA_CMN_CTRL_10 ro — Current value of cmn_plllc_ready PMA output
  [9:8] PHY_PMA_CMN_CTRL_9_8 ro — Reserved
  [7] PHY_PMA_CMN_CTRL_7 rw — Drives cmn_refclk1_rcv_out_en PMA input
  [6] PHY_PMA_CMN_CTRL_6 rw — Drives cmn_refclk_rcv_out_en PMA input
  [5] PHY_PMA_CMN_CTRL_5 ro — Current value of cmn_refclk1_active PMA output
  [4] PHY_PMA_CMN_CTRL_4 ro — Current value of cmn_refclk_active PMA output
  [3] PHY_PMA_CMN_CTRL_3 ro — Current value of cmn_plllc1_locked PMA output.
  [2] PHY_PMA_CMN_CTRL_2 ro — Current value of cmn_plllc_locked PMA output
  [1] PHY_PMA_CMN_CTRL_1 ro — Current value of cmn_macro_suspend_ack PMA output
  [0] PHY_PMA_CMN_CTRL_0 ro — Current value of cmn_ready PMA output
0xE008 PHY_PMA_ISO_CMN_PLLLC_CTRL__PHY_PMA_ISO_CMN_CTRL access per field reset 0x201 — PMA common control signal isolation register
  [31:22] PHY_PMA_ISO_CMN_PLLLC_CTRL_15_6 ro — Reserved
  [21] PHY_PMA_ISO_CMN_PLLLC_CTRL_5 rw — Drives cmn_plllc1_suspend PMA input when in PMA isolation mode.
  [20] PHY_PMA_ISO_CMN_PLLLC_CTRL_4 rw — Drives cmn_plllc_suspend PMA input when in PMA isolation mode.
  [19] PHY_PMA_ISO_CMN_PLLLC_CTRL_3 rw — Drives cmn_plllc1_mode PMA input when in PMA isolation mode.
  [18] PHY_PMA_ISO_CMN_PLLLC_CTRL_2 rw — Drives cmn_plllc_mode PMA input when in PMA isolation mode.
  [17] PHY_PMA_ISO_CMN_PLLLC_CTRL_1 rw — Drives cmn_plllc1_en PMA input when in PMA isolation mode.
  [16] PHY_PMA_ISO_CMN_PLLLC_CTRL_0 rw — Drives cmn_plllc_en PMA input when in PMA isolation mode.
  [15:14] PHY_PMA_ISO_CMN_CTRL_15_14 rw — Drives cmn_refclk1_dig_div PMA input when in PHY macro or PMA isolation mode.
  [13:12] PHY_PMA_ISO_CMN_CTRL_13_12 rw — Drives cmn_refclk_dig_div PMA input when in PHY macro or PMA isolation mode.
  [11:10] PHY_PMA_ISO_CMN_CTRL_11_10 rw — Drives cmn_refclk_dig_sel PMA input when in PHY macro or PMA isolation mode.
  [9] PHY_PMA_ISO_CMN_CTRL_9 ro — Current value of cmn_macro_pwr_en_ack PMA output.
  [8] PHY_PMA_ISO_CMN_CTRL_8 rw — Drives cmn_macro_pwr_en PMA input when in PHY macro and PMA isolation mode.
  [7] PHY_PMA_ISO_CMN_CTRL_7 rw — Drives cmn_refclk1_sel PMA input when in PHY macro and PMA isolation mode.
  [6] PHY_PMA_ISO_CMN_CTRL_6 rw — Drives cmn_refclk_sel PMA input when in PHY macro and PMA isolation mode.
  [5] PHY_PMA_ISO_CMN_CTRL_5 rw — Drives cmn_refclk1_disable PMA input when in PMA isolation mode.
  [4] PHY_PMA_ISO_CMN_CTRL_4 rw — Drives cmn_refclk_disable PMA input when in PMA isolation mode.
  [3] PHY_PMA_ISO_CMN_CTRL_3 ro — Reserved
  [2] PHY_PMA_ISO_CMN_CTRL_2 rw — Drives macro_suspend_req PMA input when in PMA isolation mode.
  [1] PHY_PMA_ISO_CMN_CTRL_1 rw — Drives cmn_macro_en PMA input when in PMA isolation mode.
  [0] PHY_PMA_ISO_CMN_CTRL_0 rw — Drives cmn_reset_n PMA input when in PMA isolation mode.
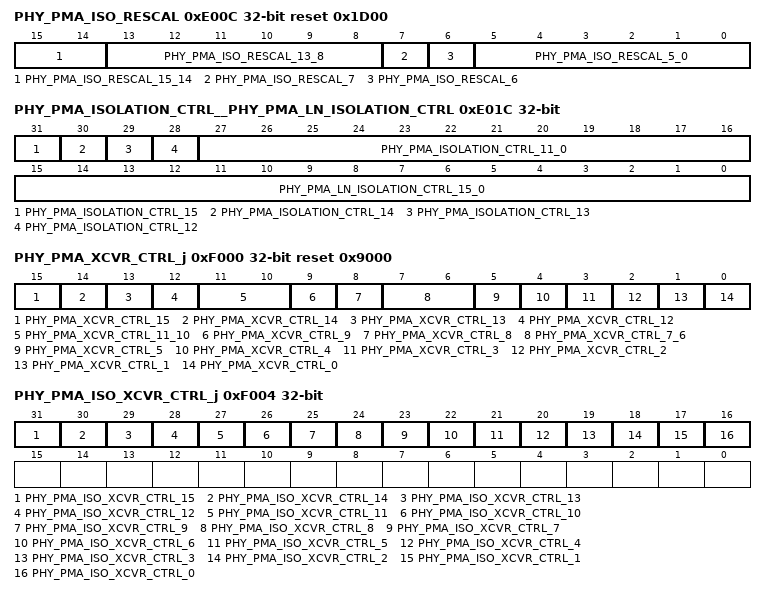
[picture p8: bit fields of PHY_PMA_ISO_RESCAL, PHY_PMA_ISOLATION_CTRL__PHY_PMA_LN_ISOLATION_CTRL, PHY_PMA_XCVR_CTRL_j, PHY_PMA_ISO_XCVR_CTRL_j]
0xE00C PHY_PMA_ISO_RESCAL access per field reset 0x1D00 — PMA Isolation resistor calibration code register
  [15:14] PHY_PMA_ISO_RESCAL_15_14 ro — Reserved.
  [13:8] PHY_PMA_ISO_RESCAL_13_8 ro — Current value cmn_rescal_code_out PMA output.
  [7] PHY_PMA_ISO_RESCAL_7 rw — Drives cmn_rescal_insel PMA input in PMA isolation mode.
  [6] PHY_PMA_ISO_RESCAL_6 ro — Reserved
  [5:0] PHY_PMA_ISO_RESCAL_5_0 rw — Drives cmn_rescal_code_in PMA input in PMA isolation mode.
0xE01C PHY_PMA_ISOLATION_CTRL__PHY_PMA_LN_ISOLATION_CTRL access per field — PMA Lane Isolation control register
  [31] PHY_PMA_ISOLATION_CTRL_15 rw — PHY/PMA isolation enable (isolation_en) - When set, enables isolation (PHY or PMA).
  [30] PHY_PMA_ISOLATION_CTRL_14 rw — PHY/PMA common isolation enable (cmn_isolation_en) - When in PHY Macro Isolation Mode, the PHY common isolation register(s) are selected.
  [29] PHY_PMA_ISOLATION_CTRL_13 ro — Reserved
  [28] PHY_PMA_ISOLATION_CTRL_12 rw — PHY/PMA isolation mode select (isolation_mode_sel) - When isolation_en is set, this bit selects between PHY isolation mode and PMA isolation mode.
  [27:16] PHY_PMA_ISOLATION_CTRL_11_0 ro — Reserved
  [15:0] PHY_PMA_LN_ISOLATION_CTRL_15_0 rw — PHY/PMA lane isolation enable (ln_isolation_en) - When in PHY Macro Isolation Mode, the selected PHY lane(s) isolation registers are selected.
0xF000 PHY_PMA_XCVR_CTRL_j access per field reset 0x9000 — PMA transceiver control register Offset = F000h + (j * 200h); where j = 0h to 1h
  [15] PHY_PMA_XCVR_CTRL_15 rw — Drives rx_termination PMA input for the associated lane when the lane is configured for Ethernet.
  [14] PHY_PMA_XCVR_CTRL_14 ro — Reserved
  [13] PHY_PMA_XCVR_CTRL_13 ro — Current value of xcvr_pll_clk_en_ack PMA output for the associated lane.
  [12] PHY_PMA_XCVR_CTRL_12 ro — Current value of xcvr_lane_en_ack PMA output for the associated lane.
  [11:10] PHY_PMA_XCVR_CTRL_11_10 ro — Reserved
  [9] PHY_PMA_XCVR_CTRL_9 rw — Drives the tx_bist_hold PMA input for all lanes in the associated link (for the master lane) - synchronized to the Tx data rate clock for the link.
  [8] PHY_PMA_XCVR_CTRL_8 rw — Drives the tx_differential_invert PMA input for the associated lane.
  [7:6] PHY_PMA_XCVR_CTRL_7_6 ro — Reserved
  [5] PHY_PMA_XCVR_CTRL_5 ro — Current value of ln_plln_locked PMA output for the associated lane
  [4] PHY_PMA_XCVR_CTRL_4 rw — Drives rx_rd10_clken PMA input for the associated lane
  [3] PHY_PMA_XCVR_CTRL_3 ro — Current value of rx_bist_status PMA output for the associated lane.
  [2] PHY_PMA_XCVR_CTRL_2 ro — Current value of rx_bist_err_toggle PMA output for the associated lane.
  [1] PHY_PMA_XCVR_CTRL_1 ro — Current value of rx_bist_sync PMA output for the associated lane.
  [0] PHY_PMA_XCVR_CTRL_0 rw — Drives the rx_differential_invert PMA input for the associated lane.
0xF004 PHY_PMA_ISO_XCVR_CTRL_j access per field — PMA Isolation Transceiver control register Offset = F004h + (j * 200h); where j = 0h to 1h
  [31] PHY_PMA_ISO_XCVR_CTRL_15 rw — Drives tx_high_z PMA input for the associated lane when in PMA isolation mode.
  [30] PHY_PMA_ISO_XCVR_CTRL_14 ro — Reserved.
  [29] PHY_PMA_ISO_XCVR_CTRL_13 rw — Drives tx_lfps_en PMA input for the associated lane when in PMA isolation mode.
  [28] PHY_PMA_ISO_XCVR_CTRL_12 rw — Drives tx_elec_idle PMA input for the associated lane when in PMA isolation mode.
  [27] PHY_PMA_ISO_XCVR_CTRL_11 ro — Current value of tx_rcv_detected PMA output for the associated lane when PHY_PMA_ISO_XCVR_CTRL[9] == 1 and PHY_PMA_ISO_XCVR_CTRL[10] == 1.
  [26] PHY_PMA_ISO_XCVR_CTRL_10 ro — Current value of tx_rcv_detect_done PMA output for the associated lane.
  [25] PHY_PMA_ISO_XCVR_CTRL_9 rw — Drives tx_rcv_detect_en PMA input for the associated lane when in PMA isolation mode.
  [24] PHY_PMA_ISO_XCVR_CTRL_8 rw — Drives xcvr_link_reset_n PMA input for the associated lane when in PMA isolation mode.
  [23] PHY_PMA_ISO_XCVR_CTRL_7 rw — Drives xcvr_pllclk_en PMA input for the associated lane when in PMA isolation mode.
  [22] PHY_PMA_ISO_XCVR_CTRL_6 ro — Reserved
  [21] PHY_PMA_ISO_XCVR_CTRL_5 rw — Drives xcvr_lane_suspend PMA input for the associated lane when in PMA isolation mode.
  [20] PHY_PMA_ISO_XCVR_CTRL_4 ro — Current value of rx_lfps_detect PMA output for the associated lane.
  [19] PHY_PMA_ISO_XCVR_CTRL_3 ro — Current value of rx_signal_detect PMA output for the associated lane.
  [18] PHY_PMA_ISO_XCVR_CTRL_2 ro — Reserved
  [17] PHY_PMA_ISO_XCVR_CTRL_1 rw — Drives rx_termination PMA input for the associated lane when in PMA isolation mode.
  [16] PHY_PMA_ISO_XCVR_CTRL_0 rw — Drives xcvr_lane_en PMA input for the associated lane when in PMA isolation mode.
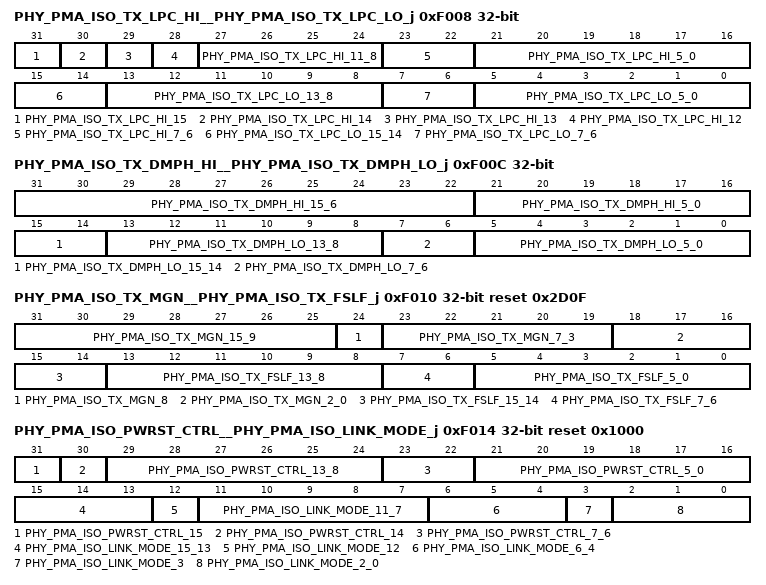
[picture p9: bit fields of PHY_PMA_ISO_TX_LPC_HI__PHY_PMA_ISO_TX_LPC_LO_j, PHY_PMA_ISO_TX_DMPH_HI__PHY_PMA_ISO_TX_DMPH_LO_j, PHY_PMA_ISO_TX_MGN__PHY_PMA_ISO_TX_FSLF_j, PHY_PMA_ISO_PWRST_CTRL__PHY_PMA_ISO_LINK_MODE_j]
0xF008 PHY_PMA_ISO_TX_LPC_HI__PHY_PMA_ISO_TX_LPC_LO_j access per field — PMA Isolation transmitter local preset coefficient register Offset = F008h + (j * 200h); where j = 0h to 1h
  [31] PHY_PMA_ISO_TX_LPC_HI_15 ro — Current value of tx_local_preset_coeff_valid PMA output for the associated lane.
  [30] PHY_PMA_ISO_TX_LPC_HI_14 ro — Reserved
  [29] PHY_PMA_ISO_TX_LPC_HI_13 rw — Drives tx_get_local_init_coef PMA input for the associated lane when in PMA isolation mode.
  [28] PHY_PMA_ISO_TX_LPC_HI_12 rw — Drives tx_get_local_preset_coef PMA input for the associated lane when in PMA isolation mode.
  [27:24] PHY_PMA_ISO_TX_LPC_HI_11_8 rw — Drives tx_local_preset_index PMA input for the associated lane when in PMA isolation mode.
  [23:22] PHY_PMA_ISO_TX_LPC_HI_7_6 ro — Reserved
  [21:16] PHY_PMA_ISO_TX_LPC_HI_5_0 ro — Current value of tx_local_tx_preset_coef[17:12] PMA output for the associated lane when (PHY_PMA_ISO_TX_LPC_HI[12] == 1 or PHY_PMA_ISO_TX_LPC_HI[13] == 1) and PHY_PMA_ISO_TX_LPC_HI[15] == 1.
  [15:14] PHY_PMA_ISO_TX_LPC_LO_15_14 ro — Reserved
  [13:8] PHY_PMA_ISO_TX_LPC_LO_13_8 ro — Current value of tx_local_tx_preset_coef[11:6] PMA output for the associated lane when (PHY_PMA_ISO_TX_LPC_HI[12] == 1 or PHY_PMA_ISO_TX_LPC_HI[13] == 1) and PHY_PMA_ISO_TX_LPC_HI[15] == 1.
  [7:6] PHY_PMA_ISO_TX_LPC_LO_7_6 ro — Reserved
  [5:0] PHY_PMA_ISO_TX_LPC_LO_5_0 ro — Current value of tx_local_tx_preset_coef[5:0] PMA output for the associated lane when (PHY_PMA_ISO_TX_LPC_HI[12] == 1 or PHY_PMA_ISO_TX_LPC_HI[13] == 1) and PHY_PMA_ISO_TX_LPC_HI[15] == 1.
0xF00C PHY_PMA_ISO_TX_DMPH_HI__PHY_PMA_ISO_TX_DMPH_LO_j access per field — PMA TX de-emphasis low isolation register Offset = F00Ch + (j * 200h); where j = 0h to 1h
  [31:22] PHY_PMA_ISO_TX_DMPH_HI_15_6 ro — Reserved
  [21:16] PHY_PMA_ISO_TX_DMPH_HI_5_0 rw — Drives tx_deemphasis[17:12] PMA input for the associated lane when in PMA isolation mode
  [15:14] PHY_PMA_ISO_TX_DMPH_LO_15_14 ro — Reserved
  [13:8] PHY_PMA_ISO_TX_DMPH_LO_13_8 rw — Drives tx_deemphasis[11:6] PMA input for the associated lane when in PMA isolation mode
  [7:6] PHY_PMA_ISO_TX_DMPH_LO_7_6 ro — Reserved
  [5:0] PHY_PMA_ISO_TX_DMPH_LO_5_0 rw — Drives tx_deemphasis[5:0] PMA input for the associated lane when in PMA isolation mode
0xF010 PHY_PMA_ISO_TX_MGN__PHY_PMA_ISO_TX_FSLF_j access per field reset 0x2D0F — PMA TX FS LF isolation register Offset = F010h + (j * 200h); where j = 0h to 1h
  [31:25] PHY_PMA_ISO_TX_MGN_15_9 ro — Reserved
  [24] PHY_PMA_ISO_TX_MGN_8 rw — Drives tx_low_power_swing_en PMA input for the associated lane when in PHY macro and PMA isolation mode.
  [23:19] PHY_PMA_ISO_TX_MGN_7_3 ro — Reserved
  [18:16] PHY_PMA_ISO_TX_MGN_2_0 rw — Drives tx_vmargin PMA input for the associated lane when in PHY macro and PMA isolation mode.
  [15:14] PHY_PMA_ISO_TX_FSLF_15_14 ro — Reserved
  [13:8] PHY_PMA_ISO_TX_FSLF_13_8 ro — Current value of tx_local_fs PMA output for the associated lane.
  [7:6] PHY_PMA_ISO_TX_FSLF_7_6 ro — Reserved
  [5:0] PHY_PMA_ISO_TX_FSLF_5_0 ro — Current value of tx_local_lf PMA output for the associated lane.
0xF014 PHY_PMA_ISO_PWRST_CTRL__PHY_PMA_ISO_LINK_MODE_j access per field reset 0x1000 — PMA Isolation mode control register Offset = F014h + (j * 200h); where j = 0h to 1h
  [31] PHY_PMA_ISO_PWRST_CTRL_15 rw — Drives rx_sig_det_en_ext_ln_{nnnn} PMA input when in PMA isolation mode.
  [30] PHY_PMA_ISO_PWRST_CTRL_14 rw — Drives tx_common_mode_en_ext_ln_{nnnn} PMA input when in PMA isolation mode.
  [29:24] PHY_PMA_ISO_PWRST_CTRL_13_8 ro — Current value of xcvr_power_state_ack_ln_{nnnn} PMA output.
  [23:22] PHY_PMA_ISO_PWRST_CTRL_7_6 ro — Reserved
  [21:16] PHY_PMA_ISO_PWRST_CTRL_5_0 rw — Drives xcvr_power_state_req_ln_{nnnn} PMA input when in PMA isolation mode.
  [15:13] PHY_PMA_ISO_LINK_MODE_15_13 ro — Reserved
  [12] PHY_PMA_ISO_LINK_MODE_12 rw — Drives xcvr_master_ln_{nnnn} PMA input when in PMA isolation mode.
  [11:7] PHY_PMA_ISO_LINK_MODE_11_7 ro — Reserved
  [6:4] PHY_PMA_ISO_LINK_MODE_6_4 rw — Drives xcvr_standard_mode_ln_{nnnn} PMA input when in PMA isolation mode.
  [3] PHY_PMA_ISO_LINK_MODE_3 ro — Reserved
  [2:0] PHY_PMA_ISO_LINK_MODE_2_0 rw — Drives xcvr_data_width_ln_{nnnn} PMA input when in PMA isolation mode.
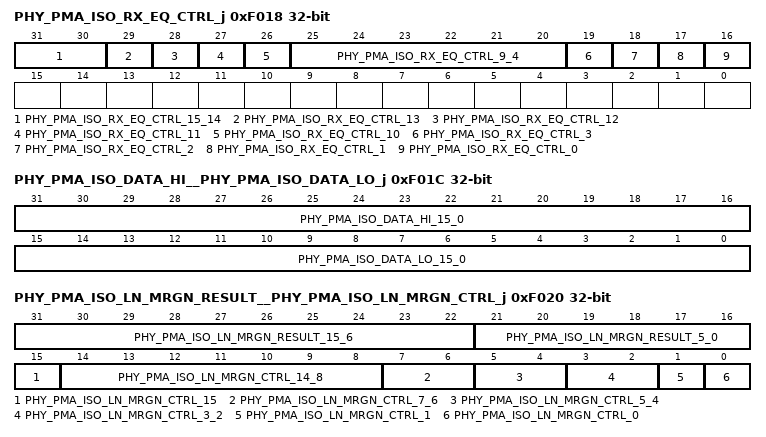
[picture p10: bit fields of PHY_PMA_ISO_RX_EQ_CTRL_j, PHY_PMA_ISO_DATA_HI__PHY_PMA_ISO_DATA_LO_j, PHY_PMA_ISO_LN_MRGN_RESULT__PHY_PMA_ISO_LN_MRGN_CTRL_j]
0xF018 PHY_PMA_ISO_RX_EQ_CTRL_j access per field — PMA RX equalization control isolation register Offset = F018h + (j * 200h); where j = 0h to 1h
  [31:30] PHY_PMA_ISO_RX_EQ_CTRL_15_14 ro — Reserved
  [29] PHY_PMA_ISO_RX_EQ_CTRL_13 rw — Drives rx_eq_training_data_valid PMA input for the associated lane when in PMA isolation mode.
  [28] PHY_PMA_ISO_RX_EQ_CTRL_12 rw — Drives rx_eq_training PMA input for the associated lane when in PMA isolation mode.
  [27] PHY_PMA_ISO_RX_EQ_CTRL_11 rw — Drives rx_eq_eval_cnt_rst PMA input for the associated lane when in PMA isolation mode.
  [26] PHY_PMA_ISO_RX_EQ_CTRL_10 ro — Reserved
  [25:20] PHY_PMA_ISO_RX_EQ_CTRL_9_4 ro — Current value of rx_link_eval_fb_dir_change PMA output for the associated lane, when PHY_PMA_ISO_RX_EQ_CTRL[0] == 1 and PHY_PMA_ISO_RX_EQ_CTRL[1] == 1. Otherwise, 0.
  [19] PHY_PMA_ISO_RX_EQ_CTRL_3 ro — Current value of rx_eq_eval_complete PMA output for the associated lane, when PHY_PMA_ISO_RX_EQ_CTRL[0] == 1 and PHY_PMA_ISO_RX_EQ_CTRL[1] == 1. Otherwise, 0.
  [18] PHY_PMA_ISO_RX_EQ_CTRL_2 rw — Drives rx_invalid_request PMA input for the associated lane when in PMA isolation mode.
  [17] PHY_PMA_ISO_RX_EQ_CTRL_1 ro — Current value of rx_eq_eval_status PMA output for the associated lane.
  [16] PHY_PMA_ISO_RX_EQ_CTRL_0 rw — Drives rx_eq_eval PMA input for the associated lane when in PMA isolation mode.
0xF01C PHY_PMA_ISO_DATA_HI__PHY_PMA_ISO_DATA_LO_j ro — PMA low data isolation register Offset = F01Ch + (j * 200h); where j = 0h to 1h
  [31:16] PHY_PMA_ISO_DATA_HI_15_0 — Current value of rx_rd[31:16] PMA output for the current lane.
  [15:0] PHY_PMA_ISO_DATA_LO_15_0 — Current value of rx_rd[15:0] PMA output for the current lane.
0xF020 PHY_PMA_ISO_LN_MRGN_RESULT__PHY_PMA_ISO_LN_MRGN_CTRL_j access per field — PMA RX lane margining control isolation register Offset = F020h + (j * 200h); where j = 0h to 1h
  [31:22] PHY_PMA_ISO_LN_MRGN_RESULT_15_6 ro — Reserved
  [21:16] PHY_PMA_ISO_LN_MRGN_RESULT_5_0 ro — Captures rx_mrgn_errcnt PMA output for the associated lane.
  [15] PHY_PMA_ISO_LN_MRGN_CTRL_15 ro — Reserved
  [14:8] PHY_PMA_ISO_LN_MRGN_CTRL_14_8 rw — Drives rx_mrgn_offset PMA input for the associated lane when in PMA isolation mode.
  [7:6] PHY_PMA_ISO_LN_MRGN_CTRL_7_6 ro — Reserved
  [5:4] PHY_PMA_ISO_LN_MRGN_CTRL_5_4 rw — Drives rx_mrgn_dir PMA input for the associated lane when in PMA isolation mode.
  [3:2] PHY_PMA_ISO_LN_MRGN_CTRL_3_2 ro — Reserved
  [1] PHY_PMA_ISO_LN_MRGN_CTRL_1 ro — Captures rx_mrgn_valid PMA output for the associated lane.
  [0] PHY_PMA_ISO_LN_MRGN_CTRL_0 rw — Drives rx_mrgn_req PMA input for the associated lane when in PMA isolation mode.
